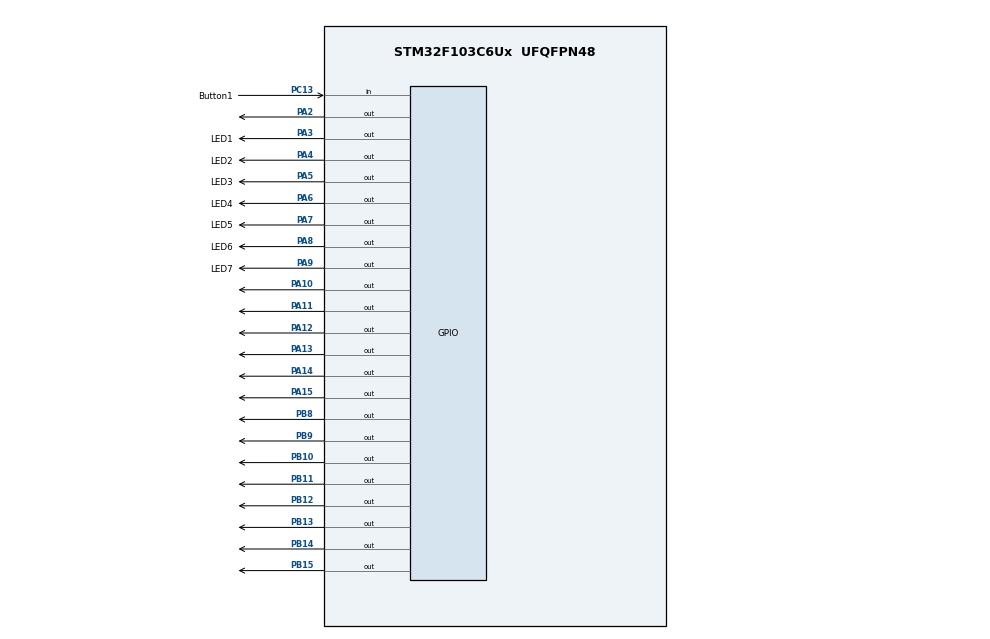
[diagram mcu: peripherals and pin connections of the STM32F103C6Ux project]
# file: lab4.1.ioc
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Mcu.Family=STM32F1
Mcu.Name=STM32F103C6Ux
Mcu.Package=UFQFPN48
NVIC.PriorityGroup=NVIC_PRIORITYGROUP_4
NVIC.TIM2_IRQn=true\:0\:0\:false\:false\:true\:true\:true
PA10.Signal=GPIO_Output
PA11.Signal=GPIO_Output
PA12.Signal=GPIO_Output
PA13.Signal=GPIO_Output
PA14.Signal=GPIO_Output
PA15.Signal=GPIO_Output
PA2.Signal=GPIO_Output
PA3.GPIO_Label=LED1
PA3.Signal=GPIO_Output
PA4.GPIO_Label=LED2
PA4.Signal=GPIO_Output
PA5.GPIO_Label=LED3
PA5.Signal=GPIO_Output
PA6.GPIO_Label=LED4
PA6.Signal=GPIO_Output
PA7.GPIO_Label=LED5
PA7.Signal=GPIO_Output
PA8.GPIO_Label=LED6
PA8.Signal=GPIO_Output
PA9.GPIO_Label=LED7
PA9.Signal=GPIO_Output
PB10.Signal=GPIO_Output
PB11.Signal=GPIO_Output
PB12.Signal=GPIO_Output
PB13.Signal=GPIO_Output
PB14.Signal=GPIO_Output
PB15.Signal=GPIO_Output
PB8.Signal=GPIO_Output
PB9.Signal=GPIO_Output
PC13-TAMPER-RTC.GPIO_Label=Button1
PC13-TAMPER-RTC.GPIO_PuPd=GPIO_PULLUP
PC13-TAMPER-RTC.Signal=GPIO_Input
ProjectManager.HeapSize=0x200
ProjectManager.StackSize=0x400
ProjectManager.TargetToolchain=STM32CubeIDE
RCC.APB1Freq_Value=8000000
RCC.APB2Freq_Value=8000000
TIM2.Period=9
TIM2.Prescaler=7999
VP_SYS_VS_ND.Mode=No_Debug
VP_TIM2_VS_ClockSourceINT.Mode=Internal
board=custom

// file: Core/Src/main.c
/* USER CODE BEGIN Header */
/**
  ******************************************************************************
  * @file           : main.c
  * @brief          : Main program body
  ******************************************************************************
  * @attention
  *
  * <h2><center>&copy; Copyright (c) 2022 STMicroelectronics.
  * All rights reserved.</center></h2>
  *
  * This software component is licensed by ST under BSD 3-Clause license,
  * the "License"; You may not use this file except in compliance with the
  * License. You may obtain a copy of the License at:
  *                        opensource.org/licenses/BSD-3-Clause
  *
  ******************************************************************************
  */
/* USER CODE END Header */
#include "main.h"

/* USER CODE BEGIN Includes */
#include "scheduler.h"
#include "functions.h"
#include "button1.h"
/* USER CODE END Includes */

TIM_HandleTypeDef htim2;

void SystemClock_Config(void);
static void MX_TIM2_Init(void);
static void MX_GPIO_Init(void);

int main(void)
{

  /* MCU Configuration--------------------------------------------------------*/

  /* Reset of all peripherals, Initializes the Flash interface and the Systick. */
  HAL_Init();

  /* Configure the system clock */
  SystemClock_Config();

  /* Initialize all configured peripherals */
  MX_TIM2_Init();
  MX_GPIO_Init();
  /* USER CODE BEGIN 2 */
  HAL_TIM_Base_Start_IT (& htim2 );
  /* USER CODE END 2 */

  /* Infinite loop */
  /* USER CODE BEGIN WHILE */
  SCH_Init();
//  SCH_Add_Task(clearLed, 100, 0);
//  SCH_Add_Task(led1, 300, 50);
//  SCH_Add_Task(led2, 400, 100);
//  SCH_Add_Task(led3, 500, 150);
//  SCH_Add_Task(led4, 600, 200);
//  SCH_Add_Task(led5, 700, 250);
//
//  SCH_Add_Task(led_oneshot, 1000, 0);
//
//  SCH_Add_Task(led_but, 10, 10);

  SCH_Add_Task(run_matrix, 0, 2);

  while (1)
  {
	  SCH_Dispatch_Tasks();
    /* USER CODE END WHILE */

  }
}

void SystemClock_Config(void)
{
  RCC_OscInitTypeDef RCC_OscInitStruct = {0};
  RCC_ClkInitTypeDef RCC_ClkInitStruct = {0};

  /** Initializes the RCC Oscillators according to the specified parameters
  * in the RCC_OscInitTypeDef structure.
  */
  RCC_OscInitStruct.OscillatorType = RCC_OSCILLATORTYPE_HSI;
  RCC_OscInitStruct.HSIState = RCC_HSI_ON;
  RCC_OscInitStruct.HSICalibrationValue = RCC_HSICALIBRATION_DEFAULT;
  RCC_OscInitStruct.PLL.PLLState = RCC_PLL_NONE;
  if (HAL_RCC_OscConfig(&RCC_OscInitStruct) != HAL_OK)
  {
    Error_Handler();
  }
  /** Initializes the CPU, AHB and APB buses clocks
  */
  RCC_ClkInitStruct.ClockType = RCC_CLOCKTYPE_HCLK|RCC_CLOCKTYPE_SYSCLK
                              |RCC_CLOCKTYPE_PCLK1|RCC_CLOCKTYPE_PCLK2;
  RCC_ClkInitStruct.SYSCLKSource = RCC_SYSCLKSOURCE_HSI;
  RCC_ClkInitStruct.AHBCLKDivider = RCC_SYSCLK_DIV1;
  RCC_ClkInitStruct.APB1CLKDivider = RCC_HCLK_DIV1;
  RCC_ClkInitStruct.APB2CLKDivider = RCC_HCLK_DIV1;

  if (HAL_RCC_ClockConfig(&RCC_ClkInitStruct, FLASH_LATENCY_0) != HAL_OK)
  {
    Error_Handler();
  }
}

static void MX_TIM2_Init(void)
{

  TIM_ClockConfigTypeDef sClockSourceConfig = {0};
  TIM_MasterConfigTypeDef sMasterConfig = {0};

  htim2.Instance = TIM2;
  htim2.Init.Prescaler = 7999;
  htim2.Init.CounterMode = TIM_COUNTERMODE_UP;
  htim2.Init.Period = 9;
  htim2.Init.ClockDivision = TIM_CLOCKDIVISION_DIV1;
  htim2.Init.AutoReloadPreload = TIM_AUTORELOAD_PRELOAD_DISABLE;
  if (HAL_TIM_Base_Init(&htim2) != HAL_OK)
  {
    Error_Handler();
  }
  sClockSourceConfig.ClockSource = TIM_CLOCKSOURCE_INTERNAL;
  if (HAL_TIM_ConfigClockSource(&htim2, &sClockSourceConfig) != HAL_OK)
  {
    Error_Handler();
  }
  sMasterConfig.MasterOutputTrigger = TIM_TRGO_RESET;
  sMasterConfig.MasterSlaveMode = TIM_MASTERSLAVEMODE_DISABLE;
  if (HAL_TIMEx_MasterConfigSynchronization(&htim2, &sMasterConfig) != HAL_OK)
  {
    Error_Handler();
  }

}

static void MX_GPIO_Init(void)
{
  GPIO_InitTypeDef GPIO_InitStruct = {0};

  /* GPIO Ports Clock Enable */
  __HAL_RCC_GPIOC_CLK_ENABLE();
  __HAL_RCC_GPIOA_CLK_ENABLE();
  __HAL_RCC_GPIOB_CLK_ENABLE();

  /*Configure GPIO pin Output Level */
  HAL_GPIO_WritePin(GPIOA, GPIO_PIN_2|LED1_Pin|LED2_Pin|LED3_Pin
                          |LED4_Pin|LED5_Pin|LED6_Pin|LED7_Pin
                          |GPIO_PIN_10|GPIO_PIN_11|GPIO_PIN_12|GPIO_PIN_13
                          |GPIO_PIN_14|GPIO_PIN_15, GPIO_PIN_RESET);

  /*Configure GPIO pin Output Level */
  HAL_GPIO_WritePin(GPIOB, GPIO_PIN_10|GPIO_PIN_11|GPIO_PIN_12|GPIO_PIN_13
                          |GPIO_PIN_14|GPIO_PIN_15|GPIO_PIN_8|GPIO_PIN_9, GPIO_PIN_RESET);

  /*Configure GPIO pin : Button1_Pin */
  GPIO_InitStruct.Pin = Button1_Pin;
  GPIO_InitStruct.Mode = GPIO_MODE_INPUT;
  GPIO_InitStruct.Pull = GPIO_PULLUP;
  HAL_GPIO_Init(Button1_GPIO_Port, &GPIO_InitStruct);

  /*Configure GPIO pins : PA2 LED1_Pin LED2_Pin LED3_Pin
                           LED4_Pin LED5_Pin LED6_Pin LED7_Pin
                           PA10 PA11 PA12 PA13
                           PA14 PA15 */
  GPIO_InitStruct.Pin = GPIO_PIN_2|LED1_Pin|LED2_Pin|LED3_Pin
                          |LED4_Pin|LED5_Pin|LED6_Pin|LED7_Pin
                          |GPIO_PIN_10|GPIO_PIN_11|GPIO_PIN_12|GPIO_PIN_13
                          |GPIO_PIN_14|GPIO_PIN_15;
  GPIO_InitStruct.Mode = GPIO_MODE_OUTPUT_PP;
  GPIO_InitStruct.Pull = GPIO_NOPULL;
  GPIO_InitStruct.Speed = GPIO_SPEED_FREQ_LOW;
  HAL_GPIO_Init(GPIOA, &GPIO_InitStruct);

  /*Configure GPIO pins : PB10 PB11 PB12 PB13
                           PB14 PB15 PB8 PB9 */
  GPIO_InitStruct.Pin = GPIO_PIN_10|GPIO_PIN_11|GPIO_PIN_12|GPIO_PIN_13
                          |GPIO_PIN_14|GPIO_PIN_15|GPIO_PIN_8|GPIO_PIN_9;
  GPIO_InitStruct.Mode = GPIO_MODE_OUTPUT_PP;
  GPIO_InitStruct.Pull = GPIO_NOPULL;
  GPIO_InitStruct.Speed = GPIO_SPEED_FREQ_LOW;
  HAL_GPIO_Init(GPIOB, &GPIO_InitStruct);

}

/* USER CODE BEGIN 4 */
void HAL_TIM_PeriodElapsedCallback(TIM_HandleTypeDef *htim){
	SCH_Update();
	getKeyInput();
}
/* USER CODE END 4 */

void Error_Handler(void)
{
  __disable_irq();
  while (1)
  {
  }
}

/************************ (C) COPYRIGHT STMicroelectronics *****END OF FILE****/
